# DMASS_BCDMA_0_LCDMA_RINGACC_CRED_45812000h register map
Vendor: Texas Instruments
Peripheral module from a debugger description file (folder am62D).
Registers are 32-bit, read-write, reset 0x0 unless marked. A register's access mark holds for its fields unless they carry their own. Offsets are as the file gives them; lines under a group give offsets from that group; [hi:lo] are bit positions; {n}, {i} and the like mark numbered series; 'fields as' and 'values as' point back to an identical list; <NAME> marks a mode.

## lcdma_ringacc_cred
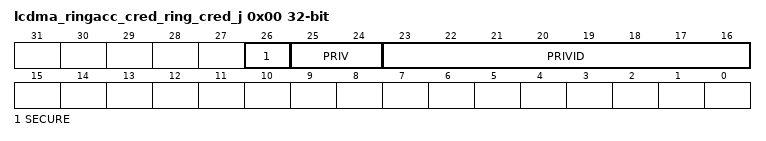
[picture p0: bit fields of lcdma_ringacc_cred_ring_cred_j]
0x00 lcdma_ringacc_cred_ring_cred_j — The Credentials Register provides credentials to be used when performing memory accesses using this flow.
  [26] SECURE — Secure attribute Reset Source: rst_mod_g_rst_n
  [25:24] PRIV — Privelege attribute Reset Source: rst_mod_g_rst_n
  [23:16] PRIVID — Privelege ID attribute Reset Source: rst_mod_g_rst_n
